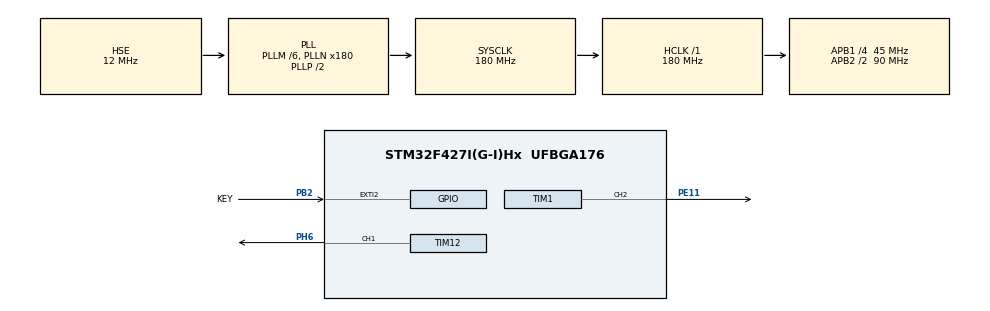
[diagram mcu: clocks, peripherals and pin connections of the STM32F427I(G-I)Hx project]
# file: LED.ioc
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IWDG.Prescaler=IWDG_PRESCALER_16
IWDG.Reload=3999
Mcu.Family=STM32F4
Mcu.Name=STM32F427I(G-I)Hx
Mcu.Package=UFBGA176
NVIC.EXTI2_IRQn=true\:2\:0\:true\:false\:true\:true\:true\:true
NVIC.PriorityGroup=NVIC_PRIORITYGROUP_4
PA13.Mode=Serial_Wire
PA13.Signal=SYS_JTMS-SWDIO
PA14.Mode=Serial_Wire
PA14.Signal=SYS_JTCK-SWCLK
PB2/BOOT1.GPIO_Label=KEY
PB2/BOOT1.GPIO_PuPd=GPIO_PULLDOWN
PB2/BOOT1.Signal=GPXTI2
PE11.Signal=S_TIM1_CH2
PH0/OSC_IN.Mode=HSE-External-Oscillator
PH0/OSC_IN.Signal=RCC_OSC_IN
PH1/OSC_OUT.Mode=HSE-External-Oscillator
PH1/OSC_OUT.Signal=RCC_OSC_OUT
PH6.Signal=S_TIM12_CH1
ProjectManager.HeapSize=0x200
ProjectManager.StackSize=0x400
ProjectManager.TargetToolchain=MDK-ARM V5.32
RCC.48MHZClocksFreq_Value=90000000
RCC.AHBFreq_Value=180000000
RCC.APB1CLKDivider=RCC_HCLK_DIV4
RCC.APB1Freq_Value=45000000
RCC.APB1TimFreq_Value=90000000
RCC.APB2CLKDivider=RCC_HCLK_DIV2
RCC.APB2Freq_Value=90000000
RCC.APB2TimFreq_Value=180000000
RCC.CortexFreq_Value=180000000
RCC.HCLKFreq_Value=180000000
RCC.HSE_VALUE=12000000
RCC.HSI_VALUE=16000000
RCC.LSE_VALUE=32768
RCC.PLLM=6
RCC.PLLN=180
RCC.PLLSourceVirtual=RCC_PLLSOURCE_HSE
RCC.SYSCLKFreq_VALUE=180000000
RCC.SYSCLKSource=RCC_SYSCLKSOURCE_PLLCLK
RCC.VCOOutputFreq_Value=360000000
SH.S_TIM12_CH1.0=TIM12_CH1,PWM Generation1 CH1
SH.S_TIM1_CH2.0=TIM1_CH2,PWM Generation2 CH2
TIM1.Channel-PWM\ Generation2\ CH2=TIM_CHANNEL_2
TIM1.OCMode_PWM-PWM\ Generation2\ CH2=TIM_OCMODE_PWM2
TIM1.Period=999
TIM1.Prescaler=179
TIM1.Pulse-PWM\ Generation2\ CH2=500
TIM12.Channel-PWM\ Generation1\ CH1=TIM_CHANNEL_1
TIM12.Prescaler=83
VP_IWDG_VS_IWDG.Mode=IWDG_Activate
VP_TIM1_VS_ClockSourceINT.Mode=Internal
board=custom

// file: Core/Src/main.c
/* USER CODE BEGIN Header */
/**
  ******************************************************************************
  * @file           : main.c
  * @brief          : Main program body
  ******************************************************************************
  * @attention
  *
  * Copyright (c) 2026 STMicroelectronics.
  * All rights reserved.
  *
  * This software is licensed under terms that can be found in the LICENSE file
  * in the root directory of this software component.
  * If no LICENSE file comes with this software, it is provided AS-IS.
  *
  ******************************************************************************
  */
/* USER CODE END Header */
#include "main.h"
#include "iwdg.h"
#include "tim.h"
#include "gpio.h"

/* USER CODE BEGIN PV */
#define LED_R_PIN GPIO_PIN_11
#define LED_R_GPIO_PORT GPIOE
volatile uint8_t requested_mode = 0;
/* USER CODE END PV */

void SystemClock_Config(void);

/* USER CODE BEGIN 0 */
static void decideBrightness(uint32_t pulse)
{
  __HAL_TIM_SET_COMPARE(&htim1, TIM_CHANNEL_2, pulse);
}

static void UpdateLed(uint8_t mode,uint32_t now)
{
  // uint32_t now = HAL_GetTick();
  static uint8_t activeMode = 0;
  static uint32_t breathtick =0;
  static int32_t brightness = 0;
  static int32_t step=10;

  static uint32_t blink_tick =0;
  static uint8_t blink_on = 0;

  if (mode!=activeMode)
  {
    activeMode = mode;
    brightness = 0;
    step =10;
    breathtick =now;

    blink_on=1;
    blink_tick =now;

    if (mode ==2 )
    {
      decideBrightness(500);
    }
    else
    {
      decideBrightness((0));
    }
  }

  switch (mode)
  {
  case 0:
    break;
  case 1:
    if ((uint32_t)(now - breathtick) >= 10U)
    {
      breathtick = now;
      brightness += step;

      if (brightness >= 1000)
      {
        brightness = 1000;
        step = -10;
      }
      else if (brightness <= 0)
      {
        brightness = 0;
        step = 10;
      }

      decideBrightness((uint32_t)brightness);
    }
    break;
  case 2:
    if ((uint32_t)(now - blink_tick) >= 500U)
    {
      blink_tick = now;
      blink_on = !blink_on;

      decideBrightness(blink_on ? 500U : 0U);
    }
    break;
  default:
    decideBrightness((0));
    break;

  }
}

/* USER CODE END 0 */

int main(void)
{

  /* MCU Configuration--------------------------------------------------------*/

  /* Reset of all peripherals, Initializes the Flash interface and the Systick. */
  HAL_Init();

  /* Configure the system clock */
  SystemClock_Config();

  /* Initialize all configured peripherals */
  MX_GPIO_Init();
  MX_TIM1_Init();
  MX_TIM12_Init();
  MX_IWDG_Init();
  /* USER CODE BEGIN 2 */
  // HAL_TIM_PWM_Start(&htim1, TIM_CHANNEL_2);//启动PWM

  decideBrightness(0);

  if (HAL_TIM_PWM_Start(&htim1, TIM_CHANNEL_2) != HAL_OK)
  {
    Error_Handler();
  }

  /* USER CODE END 2 */

  /* Infinite loop */
  /* USER CODE BEGIN WHILE */
  while (1)
  {
    uint32_t now = HAL_GetTick();

    uint8_t mode = requested_mode;
    UpdateLed(mode,now);

    if (HAL_GPIO_ReadPin(KEY_GPIO_Port, KEY_Pin) == GPIO_PIN_SET)
    {
      HAL_IWDG_Refresh(&hiwdg);
    }

    /* USER CODE END WHILE */

  }
}

void SystemClock_Config(void)
{
  RCC_OscInitTypeDef RCC_OscInitStruct = {0};
  RCC_ClkInitTypeDef RCC_ClkInitStruct = {0};

  /** Configure the main internal regulator output voltage
  */
  __HAL_RCC_PWR_CLK_ENABLE();
  __HAL_PWR_VOLTAGESCALING_CONFIG(PWR_REGULATOR_VOLTAGE_SCALE1);

  /** Initializes the RCC Oscillators according to the specified parameters
  * in the RCC_OscInitTypeDef structure.
  */
  RCC_OscInitStruct.OscillatorType = RCC_OSCILLATORTYPE_LSI|RCC_OSCILLATORTYPE_HSE;
  RCC_OscInitStruct.HSEState = RCC_HSE_ON;
  RCC_OscInitStruct.LSIState = RCC_LSI_ON;
  RCC_OscInitStruct.PLL.PLLState = RCC_PLL_ON;
  RCC_OscInitStruct.PLL.PLLSource = RCC_PLLSOURCE_HSE;
  RCC_OscInitStruct.PLL.PLLM = 6;
  RCC_OscInitStruct.PLL.PLLN = 180;
  RCC_OscInitStruct.PLL.PLLP = RCC_PLLP_DIV2;
  RCC_OscInitStruct.PLL.PLLQ = 4;
  if (HAL_RCC_OscConfig(&RCC_OscInitStruct) != HAL_OK)
  {
    Error_Handler();
  }

  /** Activate the Over-Drive mode
  */
  if (HAL_PWREx_EnableOverDrive() != HAL_OK)
  {
    Error_Handler();
  }

  /** Initializes the CPU, AHB and APB buses clocks
  */
  RCC_ClkInitStruct.ClockType = RCC_CLOCKTYPE_HCLK|RCC_CLOCKTYPE_SYSCLK
                              |RCC_CLOCKTYPE_PCLK1|RCC_CLOCKTYPE_PCLK2;
  RCC_ClkInitStruct.SYSCLKSource = RCC_SYSCLKSOURCE_PLLCLK;
  RCC_ClkInitStruct.AHBCLKDivider = RCC_SYSCLK_DIV1;
  RCC_ClkInitStruct.APB1CLKDivider = RCC_HCLK_DIV4;
  RCC_ClkInitStruct.APB2CLKDivider = RCC_HCLK_DIV2;

  if (HAL_RCC_ClockConfig(&RCC_ClkInitStruct, FLASH_LATENCY_5) != HAL_OK)
  {
    Error_Handler();
  }
}

/* USER CODE BEGIN 4 */

// void HAL_TIM_PeriodElapsedCallback(TIM_HandleTypeDef *htim)
// {
//   if (htim1.Instance == TIM1)
//   {
//     HAL_GPIO_TogglePin(LED_R_GPIO_PORT, LED_R_PIN);
//   }
// }
/* USER CODE END 4 */

void Error_Handler(void)
{
  __disable_irq();
  while (1)
  {
  }
}
